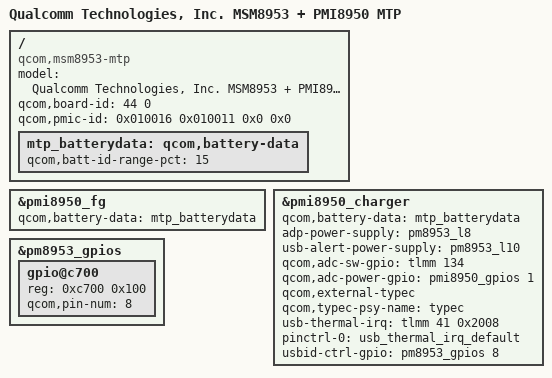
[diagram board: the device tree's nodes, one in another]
/*
 * Copyright (c) 2015-2017, The Linux Foundation. All rights reserved.
 *
 * This program is free software; you can redistribute it and/or modify
 * it under the terms of the GNU General Public License version 2 and
 * only version 2 as published by the Free Software Foundation.
 *
 * This program is distributed in the hope that it will be useful,
 * but WITHOUT ANY WARRANTY; without even the implied warranty of
 * MERCHANTABILITY or FITNESS FOR A PARTICULAR PURPOSE.  See the
 * GNU General Public License for more details.
 */

/dts-v1/;

#include "msm8953-ZS550KL-PR.dtsi"
#include "msm-pmi8950.dtsi"
#include "msm8953-ZS550KL-PR-mtp.dtsi"
#include "msm8953-pmi8950.dtsi"
#include "msm8953-ZS550KL-camera-sensor-mtp.dtsi"

/ {
	model = "Qualcomm Technologies, Inc. MSM8953 + PMI8950 MTP";
	compatible = "qcom,msm8953-mtp", "qcom,msm8953", "qcom,mtp";
	qcom,board-id= <44 0>;
       qcom,pmic-id = <0x010016 0x010011 0x0 0x0>;
};

/{
       mtp_batterydata: qcom,battery-data {
               qcom,batt-id-range-pct = <15>;
               #include "batterydata-itech-3000mah.dtsi"
               #include "2446501_Asus_Aquarius_3000mAh_averaged_MasterSlave_May26th2016_PMI8952GUI20016.dtsi"
       };
};

&pmi8950_fg {
       qcom,battery-data = <&mtp_batterydata>;
};

&pmi8950_charger {
       qcom,battery-data = <&mtp_batterydata>;
       adp-power-supply = <&pm8953_l8>;
       usb-alert-power-supply = <&pm8953_l10>;
       qcom,adc-sw-gpio=<&tlmm 134 0x0>;
       qcom,adc-power-gpio=<&pmi8950_gpios 1 0x0>;
       //qcom,chg-led-sw-controls;
       //qcom,chg-led-support;
       qcom,external-typec;
       qcom,typec-psy-name = "typec";
       usb-thermal-irq = <&tlmm 41 0x2008>;
       pinctrl-names = "default";
       pinctrl-0 = <&usb_thermal_irq_default>;
       usbid-ctrl-gpio=<&pm8953_gpios 8 0x0>;
};

&pm8953_gpios {
	/* GPIO 8 (USBID_CTRL) */
	gpio@c700 {
		reg = <0xc700 0x100>;
		qcom,pin-num = <8>;
		status = "okay";
	};
};
